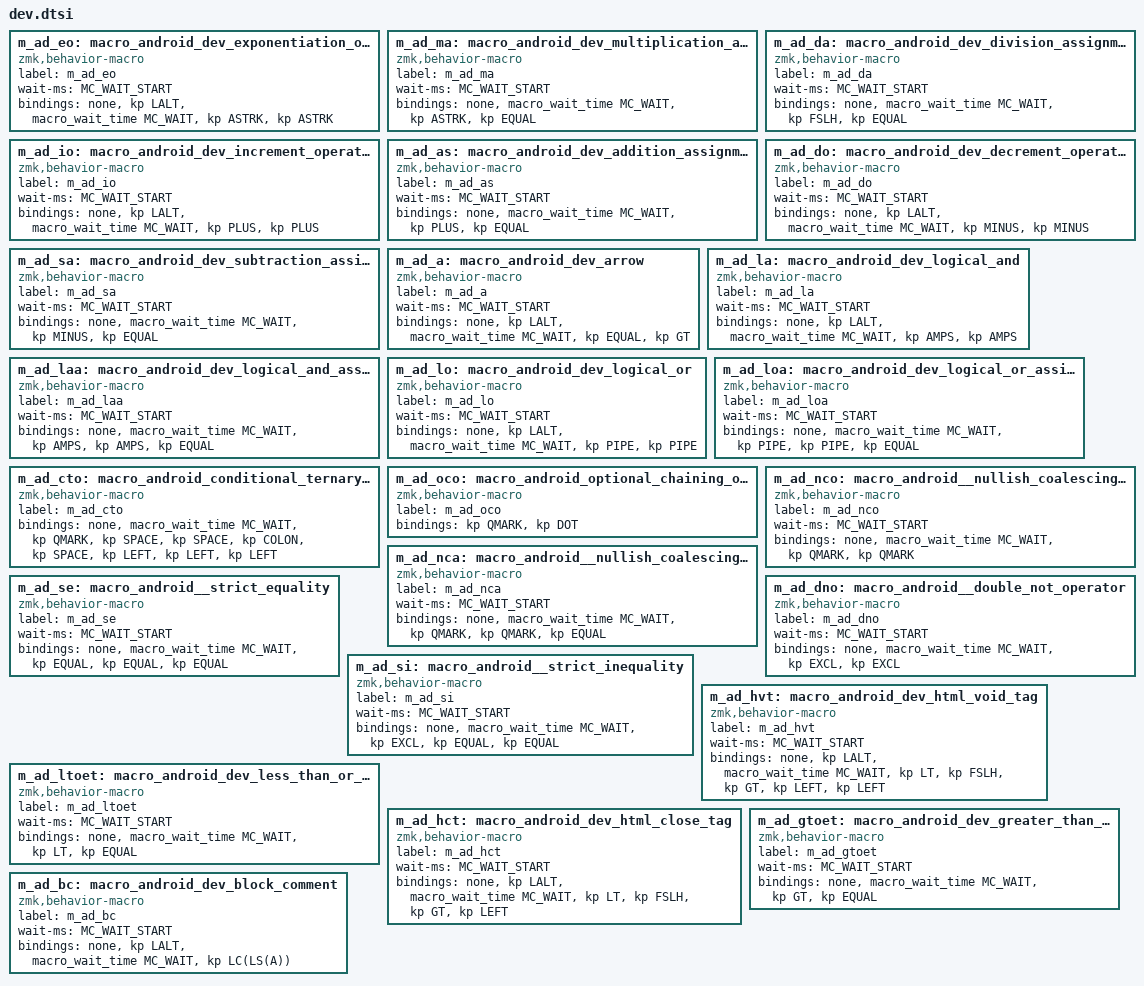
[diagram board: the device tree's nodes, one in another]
// action: **
m_ad_eo: macro_android_dev_exponentiation_operator {
    compatible = "zmk,behavior-macro";
    label = "m_ad_eo";
    #binding-cells = <0>;
    wait-ms = <MC_WAIT_START>;
    bindings
        = <&none &kp LALT> /* ALT fix for VSCode */
        , <&macro_wait_time MC_WAIT>
        , <&kp ASTRK &kp ASTRK>;
};

// action: *=
m_ad_ma: macro_android_dev_multiplication_assignment {
    compatible = "zmk,behavior-macro";
    label = "m_ad_ma";
    #binding-cells = <0>;
    wait-ms = <MC_WAIT_START>;
    bindings
        = <&none>
        , <&macro_wait_time MC_WAIT>
        , <&kp ASTRK &kp EQUAL>;
};

// action: /=
m_ad_da: macro_android_dev_division_assignment {
    compatible = "zmk,behavior-macro";
    label = "m_ad_da";
    #binding-cells = <0>;
    wait-ms = <MC_WAIT_START>;
    bindings
        = <&none>
        , <&macro_wait_time MC_WAIT>
        , <&kp FSLH &kp EQUAL>;
};

// action: ++
m_ad_io: macro_android_dev_increment_operator {
    compatible = "zmk,behavior-macro";
    label = "m_ad_io";
    #binding-cells = <0>;
    wait-ms = <MC_WAIT_START>;
    bindings
        = <&none &kp LALT> /* ALT fix for VSCode */
        , <&macro_wait_time MC_WAIT>
        , <&kp PLUS &kp PLUS>;
};

// action: +=
m_ad_as: macro_android_dev_addition_assignment {
    compatible = "zmk,behavior-macro";
    label = "m_ad_as";
    #binding-cells = <0>;
    wait-ms = <MC_WAIT_START>;
    bindings
        = <&none>
        , <&macro_wait_time MC_WAIT>
        , <&kp PLUS &kp EQUAL>;
};

// action: --
m_ad_do: macro_android_dev_decrement_operator {
    compatible = "zmk,behavior-macro";
    label = "m_ad_do";
    #binding-cells = <0>;
    wait-ms = <MC_WAIT_START>;
    bindings
        = <&none &kp LALT> /* ALT fix for VSCode */
        , <&macro_wait_time MC_WAIT>
        , <&kp MINUS &kp MINUS>;
};

// action: -=
m_ad_sa: macro_android_dev_subtraction_assignment {
    compatible = "zmk,behavior-macro";
    label = "m_ad_sa";
    #binding-cells = <0>;
    wait-ms = <MC_WAIT_START>;
    bindings
        = <&none>
        , <&macro_wait_time MC_WAIT>
        , <&kp MINUS &kp EQUAL>;
};

// action: =>
m_ad_a: macro_android_dev_arrow {
    compatible = "zmk,behavior-macro";
    label = "m_ad_a";
    #binding-cells = <0>;
    wait-ms = <MC_WAIT_START>;
    bindings
        = <&none &kp LALT> /* ALT fix for VSCode */
        , <&macro_wait_time MC_WAIT>
        , <&kp EQUAL &kp GT>;
};

// action: &&
m_ad_la: macro_android_dev_logical_and {
    compatible = "zmk,behavior-macro";
    label = "m_ad_la";
    #binding-cells = <0>;
    wait-ms = <MC_WAIT_START>;
    bindings
        = <&none &kp LALT> /* ALT fix for VSCode */
        , <&macro_wait_time MC_WAIT>
        , <&kp AMPS &kp AMPS>;
};

// action: &&=
m_ad_laa: macro_android_dev_logical_and_assignment {
    compatible = "zmk,behavior-macro";
    label = "m_ad_laa";
    #binding-cells = <0>;
    wait-ms = <MC_WAIT_START>;
    bindings
        = <&none>
        , <&macro_wait_time MC_WAIT>
        , <&kp AMPS &kp AMPS &kp EQUAL>;
};

// action: ||
m_ad_lo: macro_android_dev_logical_or {
    compatible = "zmk,behavior-macro";
    label = "m_ad_lo";
    #binding-cells = <0>;
    wait-ms = <MC_WAIT_START>;
    bindings
        = <&none &kp LALT> /* ALT fix for VSCode */
        , <&macro_wait_time MC_WAIT>
        , <&kp PIPE &kp PIPE>;
};

// action: ||=
m_ad_loa: macro_android_dev_logical_or_assignment {
    compatible = "zmk,behavior-macro";
    label = "m_ad_loa";
    #binding-cells = <0>;
    wait-ms = <MC_WAIT_START>;
    bindings
        = <&none>
        , <&macro_wait_time MC_WAIT>
        , <&kp PIPE &kp PIPE &kp EQUAL>;
};

// action: ?░:░
m_ad_cto: macro_android_conditional_ternary_operator {
    compatible = "zmk,behavior-macro";
    label = "m_ad_cto";
    #binding-cells = <0>;
    bindings
        = <&none>
        , <&macro_wait_time MC_WAIT>
        , <&kp QMARK &kp SPACE &kp SPACE &kp COLON &kp SPACE>
        , <&kp LEFT &kp LEFT &kp LEFT>;
};

// action: ?.
m_ad_oco: macro_android_optional_chaining_operator {
    compatible = "zmk,behavior-macro";
    label = "m_ad_oco";
    #binding-cells = <0>;
    bindings
        = <&kp QMARK &kp DOT>;
};

// action: ??
m_ad_nco: macro_android__nullish_coalescing_operator {
    compatible = "zmk,behavior-macro";
    label = "m_ad_nco";
    #binding-cells = <0>;
    wait-ms = <MC_WAIT_START>;
    bindings
        = <&none>
        , <&macro_wait_time MC_WAIT>
        , <&kp QMARK &kp QMARK>;
};

// action: ??=
m_ad_nca: macro_android__nullish_coalescing_assignment {
    compatible = "zmk,behavior-macro";
    label = "m_ad_nca";
    #binding-cells = <0>;
    wait-ms = <MC_WAIT_START>;
    bindings
        = <&none>
        , <&macro_wait_time MC_WAIT>
        , <&kp QMARK &kp QMARK &kp EQUAL>;
};

// action: ===
m_ad_se: macro_android__strict_equality {
    compatible = "zmk,behavior-macro";
    label = "m_ad_se";
    #binding-cells = <0>;
    wait-ms = <MC_WAIT_START>;
    bindings
        = <&none>
        , <&macro_wait_time MC_WAIT>
        , <&kp EQUAL &kp EQUAL &kp EQUAL>;
};

// action: !!
m_ad_dno: macro_android__double_not_operator {
    compatible = "zmk,behavior-macro";
    label = "m_ad_dno";
    #binding-cells = <0>;
    wait-ms = <MC_WAIT_START>;
    bindings
        = <&none>
        , <&macro_wait_time MC_WAIT>
        , <&kp EXCL &kp EXCL>;
};

// action: !==
m_ad_si: macro_android__strict_inequality {
    compatible = "zmk,behavior-macro";
    label = "m_ad_si";
    #binding-cells = <0>;
    wait-ms = <MC_WAIT_START>;
    bindings
        = <&none>
        , <&macro_wait_time MC_WAIT>
        , <&kp EXCL &kp EQUAL &kp EQUAL>;
};

// action: <░/>
m_ad_hvt: macro_android_dev_html_void_tag {
    compatible = "zmk,behavior-macro";
    label = "m_ad_hvt";
    #binding-cells = <0>;
    wait-ms = <MC_WAIT_START>;
    bindings
        = <&none &kp LALT> /* ALT fix for VSCode */
        , <&macro_wait_time MC_WAIT>
        , <&kp LT &kp FSLH &kp GT>
        , <&kp LEFT &kp LEFT>;
};

// action: <=
m_ad_ltoet: macro_android_dev_less_than_or_equal_to {
    compatible = "zmk,behavior-macro";
    label = "m_ad_ltoet";
    #binding-cells = <0>;
    wait-ms = <MC_WAIT_START>;
    bindings
        = <&none>
        , <&macro_wait_time MC_WAIT>
        , <&kp LT &kp EQUAL>;
};

// action: </░>
m_ad_hct: macro_android_dev_html_close_tag {
    compatible = "zmk,behavior-macro";
    label = "m_ad_hct";
    #binding-cells = <0>;
    wait-ms = <MC_WAIT_START>;
    bindings
        = <&none &kp LALT> /* ALT fix for VSCode */
        , <&macro_wait_time MC_WAIT>
        , <&kp LT &kp FSLH &kp GT>
        , <&kp LEFT>;
};

// action: >=
m_ad_gtoet: macro_android_dev_greater_than_or_equal_to {
    compatible = "zmk,behavior-macro";
    label = "m_ad_gtoet";
    #binding-cells = <0>;
    wait-ms = <MC_WAIT_START>;
    bindings
        = <&none>
        , <&macro_wait_time MC_WAIT>
        , <&kp GT &kp EQUAL>;
};

// action: /* block comment */
m_ad_bc: macro_android_dev_block_comment {
    compatible = "zmk,behavior-macro";
    label = "m_ad_bc";
    #binding-cells = <0>;
    wait-ms = <MC_WAIT_START>;
    bindings
        = <&none &kp LALT> /* ALT fix for VSCode */
        , <&macro_wait_time MC_WAIT>
        , <&kp LC(LS(A))>;
};
